# ADuCM322i register map
Vendor: Analog Devices Inc.; Series: ARMCM3; File version: 1.0
CPU: CM3 r2p1, little endian, no MPU, no FPU, 3 interrupt priority bits
Registers are 16-bit, read-write, no defined reset value unless marked. A register's access mark holds for its fields unless they carry their own. Offsets are from the block's base; [hi:lo] are bit positions.

## FEE — Flash Controller
Base 0x40018000
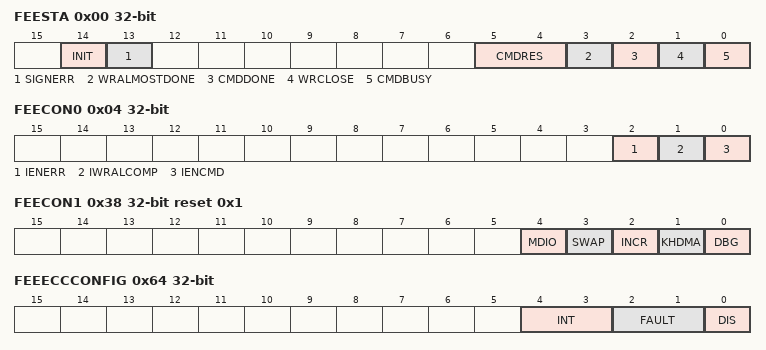
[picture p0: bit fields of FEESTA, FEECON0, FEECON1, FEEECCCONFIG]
0x00 FEESTA 32-bit ro read-modifies — Status register
  [14] INIT range 0x00000000..0x00000001 — Initialization upload in progress.
  [13] SIGNERR range 0x00000000..0x00000001 — Information space signature check on reset error.
  [5:4] CMDRES — These two bits indicate the status of a command on completion or the status of a write.
    0=SUCCESS (Successful completion of a command or a write); 1=IGNORED (Attempted signcheck, write or erase of a protected location.); 2=READERROR (Read verify error. After an erase the controller reads the corresponding word(s) to verify that the transaction completed successfully. If data read is not all 'F's this is the resulting status.If the Sign command is executed and the resulting signature does not match the data in the upper 4 bytes of the upper page in a block then this is the resulting status.); 3=ABORTED (Indicates that a command or a write was aborted by an abort command or a system interrupt has caused an abort)
  [3] WRALMOSTDONE — Write almost Complete - key-hole registers open for access. This bit flags the earliest point at which the flash controller data and address may be updated for the next command without affecting an active flash command operation.
    0=CLR (Cleared to 0 when read); 1=SET (Set to 1 when a write completes)
  [2] CMDDONE — This bit asserts when a command completes.
    0=CLR (Cleared to 0 when read); 1=SET (Set to 1 when a command completes)
  [1] WRCLOSE range 0x00000000..0x00000001 — This bit is asserted when the user has written all key-hole registers for flash write and the controller has started the write.
  [0] CMDBUSY range 0x00000000..0x00000001 — Command busy.
0x04 FEECON0 32-bit — Command Control register: interrupt enable register
  [all] fields
    0=DIS (Disable); 1=EN (Enable)
  [2] IENERR — Command fail interrupt enable
  [1] IWRALCOMP — Write almost complete interrupt enable
  [0] IENCMD — Command complete interrupt enable
0x08 FEECMD 32-bit — Command register
  [4:0] CMD — Commands
    0=IDLE (No command executed.); 1=PAGEERASE (Write the address of the page to be erased to the FEEADR0 register, then write this code to the FEECMD and the flash will erase the page. When the erase has completed the flash will read every location in the page to verify all words in the page are erased. If there is a read verify error this will be indicated in the Status register. To erase multiple pages wait until a previous page erase has completed - check the status then issue a command to start the next page erase. Before entering this command 0xF123F456 must first be written to the FEEKEY register.); 2=SIGN (Use this command to generate a signature for a block of data. The signature is generated on a page by page basis. To generate a signature the address of the first page of the block is entered in the FEEADR0 register, the address of the last page is written to the FEEADR1 register, then write this code to the FEECMD register. When the command has completed the signature is available for reading in the Sign register. The last 4 bytes of the last page in a block is reserved for storing the signature. Before entering this command 0xF123F456 must first be written to the FEEKEY register.); 4=WRITE (Use this command to write to flash locations. This command needs a UserKey for writing into write protection location and userfaakey location. No key is required for other flash locations. This command takes the address, data from FEEADR, FEEFLDATA key-hole registers.); 5=MASSERASE0 (Erase all of flash0 user space. To enable this operation 0xF123F456 must first be written to the FEEKEY register (this is to prevent accidental erases). When the mass erase has completed the controller will read every location to verify that all locations are 0xFFFFFFFFFFFFFFFF. If there is a read verify error this will be indicated in the Status register.); 6=MASSERASE1 (Erase all of flash1 user space. To enable this operation 0xF123F456 must first be written to the FEEKEY register (this is to prevent accidental erases). When the mass erase has completed the controller will read every location to verify that all locations are 0xFFFFFFFFFFFFFFFF. If there is a read verify error this will be indicated in the Status register.); 8=ABORT (If this command is issued then any command currently in progress will be stopped. The status will indicate command completed with an error status (FEESTA[5:4] = 0x3). Note that this is the only command that can be issued while another command is already in progress. This command can also be used to stop a write that may be in progress. If a write or erase is aborted then the flash timing will be violated and it is not possible to determine if the write or erase completed successfully. To enable this operation 0xF123F456 must first be written to the FEEKEY register (this is to prevent accidental aborts).)
0x0C FEEFLADR 32-bit — Flash address key - hole register
  [18:3] FLAddr range 0x00000000..0x0000FFFF — Memory mapped address for the flash location
0x10 FEEFLDATA0 32-bit — Flash Data register: key-hole interface lower 32 bits
  [31:0] FLDATA0 range 0x00000000..0xFFFFFFFF — FLDATA0 forms the lower 32 bit of 64 bit data to be written to flash
0x14 FEEFLDATA1 32-bit — Flash Data register: key-hole interface upper 32 bits
  [31:0] FLDATA1 range 0x00000000..0xFFFFFFFF — FLDATA1 forms the upper 32 bit of 64 bit data to be written to flash
0x18 FEEADR0 32-bit — Lower page address register
  [18:11] PageAddr0 range 0x00000000..0x000000FF — Used by SIGN and PAGEERASE commands for specifying page address. See the description of these commands in FEECMD
0x1C FEEADR1 32-bit — Upper page address register
  [18:11] PageAddr1 range 0x00000000..0x000000FF — Used by SIGN command for specifying the end page address. See description of this command in FEECMD
0x20 FEEKEY 32-bit wo — Flash Key register.
  [31:0] KEY range 0x00000000..0xFFFFFFFF — Enter 0xF123F456 to allow key protected operations. Returns 0x0 if read.
0x28 FEEPRO0 32-bit reset 0xFFFFFFFF (reset mask 0x0) — write protection register for flash0
  [31:0] WrProt0 range 0x00000000..0xFFFFFFFF — Write protection for flash0 - 32 bits.
0x2C FEEPRO1 32-bit reset 0xFFFFFFFF (reset mask 0x0) — write protection register for flash1
  [31:0] WrProt1 range 0x00000000..0xFFFFFFFF — Write protection for flash1 - 32 bits.
0x34 FEESIG 32-bit ro — Flash Signature
  [23:0] SIGN range 0x00000000..0x00FFFFFF — 24 bit signature.
0x38 FEECON1 32-bit reset 0x1 (reset mask 0x0) — User Setup register
  [4] MDIO ro range 0x00000000..0x00000001 — MDIO mode
  [3] SWAP ro range 0x00000000..0x00000001 — Swap program code for MDIO mode.
  [2] INCR — Auto increment FEEFLAADR for non DMA operation.
    0=DIS (Disable auto address increment); 1=EN (Enable auto address increment)
  [1] KHDMA — Key-hole DMA enable.
    0=DIS (Disable DMA mode); 1=EN (Enable DMA mode)
  [0] DBG — JTAG debug enable
    0=DIS (Disable JTAG access); 1=EN (Enable JTAG access)
0x40 FEEWRADDRA 32-bit ro — write abort address register
  [31:0] WrAbortAddr range 0x00000000..0xFFFFFFFF — If a write is aborted then this will contain the address of the location been written when the write was aborted. This register has appropriate value if command abort happened. This has to be read after the command is aborted. And this has to be read before any other command is given. After reset the value will be random.
0x48 FEEAEN0 32-bit — Interrupt abort enable register. Interrupt 31 to Interrupt 0.
  [31:0] SysIrqAbortEn range 0x00000000..0xFFFFFFFF — Lower 32 bits of System Interrupt Abort Enable. To allow a system interrupt to abort a command (write, erase, sign or mass verify) then write a '1' to the appropriate bit in this register.
0x4C FEEAEN1 32-bit — Interrupt abort enable register. Interrupt 54 to Interrupt 32.
  [22:0] SysIrqAbortEn range 0x00000000..0x007FFFFF — Upper 23 bits of System Interrupt Abort Enable. To allow a system interrupt to abort a command (write, erase, sign or mass verify) then write a '1' to the appropriate bit in this register.
0x64 FEEECCCONFIG 32-bit — Configurable ECC enable/disable, error response
  [4:3] INT range 0x00000000..0x00000003 — Interrupt enable when a ECC error happens during an AHB read from program or data flash.
  [2:1] FAULT range 0x00000000..0x00000003 — Signifies when to generate AHB error (HRESP = 1) when an ECC error happens - 1 bit error or 2 bit error.
  [0] DIS range 0x00000000..0x00000001 — ECC Disable bit.
0x74 FEEECCADDR0 32-bit ro — Flash 0 ECC Error Address
  [18:0] ADDR0 range 0x00000000..0x0007FFFF — This register has the address of flash0 for which ECC error is detected.
0x78 FEEECCADDR1 32-bit ro — Flash 1 ECC Error Address
  [18:0] ADDR1 range 0x00000000..0x0007FFFF — This register has the address of flash1 for which ECC error is detected.
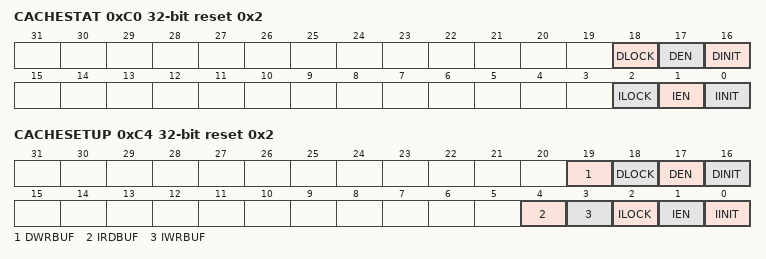
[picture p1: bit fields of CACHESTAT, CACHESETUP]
0xC0 CACHESTAT 32-bit ro reset 0x2 (reset mask 0x0) — Cache Status register
  [18] DLOCK range 0x00000000..0x00000001 — This bit is set when D-Cache is locked and cleared when D-cache is unlocked.
  [17] DEN range 0x00000000..0x00000001 — If this bit is set then D-Cache is enabled and when cleared D-Cache is disabled. This is also cleared when CACHESTAT[16] is set.
  [16] DINIT range 0x00000000..0x00000001 — It is set when D-cache memory initialization starts and clears when initialization is done. D-Cache is disabled when this bit is set.
  [2] ILOCK range 0x00000000..0x00000001 — This bit is set when I-Cache is locked and cleared when I-cache is unlocked.
  [1] IEN range 0x00000000..0x00000001 — If this bit is set then I-Cache is enabled and when cleared I-Cache is disabled. This is also cleared when CACHESTAT[0] is set.
  [0] IINIT range 0x00000000..0x00000001 — It is set when I-cache memory initialization starts and clears when initialization is done. I-Cache is disabled when this bit is set.
0xC4 CACHESETUP 32-bit reset 0x2 (reset mask 0x0)
  [19] DWRBUF — If this bit is set, then for every AHB access, hit from WrBuffer is not checked.
    0=EN; 1=DIS
  [18] DLOCK range 0x00000000..0x00000001 — If this bit is set, then D-cache contents are locked. Any new misses will not be replaced in D-Cache. This bit is cleared when CACHESETUP[16] is set.
  [17] DEN range 0x00000000..0x00000001 — If this bit set, then D-Cache is enabled for AHB accesses. If 0, then D-cache is disabled, and all AHB accesses will be via Flash memory. This bit is cleared when CACHESETUP[16] is set.
  [16] DINIT range 0x00000000..0x00000001 — If this bit is set then the D-cache contents are initialized to all zeros. This bit will be cleared once the initialization starts.
  [4] IRDBUF — If this bit is set, then for every AHB access, hit from Read Buffer is not checked.
    0=EN; 1=DIS
  [3] IWRBUF — If this bit is set, then for every AHB access, hit from Write Buffer is not checked.
    0=EN; 1=DIS
  [2] ILOCK range 0x00000000..0x00000001 — If this bit is set, then I-cache contents are locked. Any new misses will not be replaced in I-Cache. This bit is cleared when CACHESETUP[0] is set.
  [1] IEN range 0x00000000..0x00000001 — If this bit set, then I-Cache is enabled for AHB accesses. If 0, then I-cache is disabled, and all AHB accesses will be via Flash memory. This bit is cleared when CACHESETUP[0] is set.
  [0] IINIT range 0x00000000..0x00000001 — If this bit is set then the I-cache contents are initialized to all zeros. This bit will be cleared once the initialization starts.
0xC8 CACHEKEY 32-bit wo
  [31:0] Key range 0x00000000..0xFFFFFFFF
